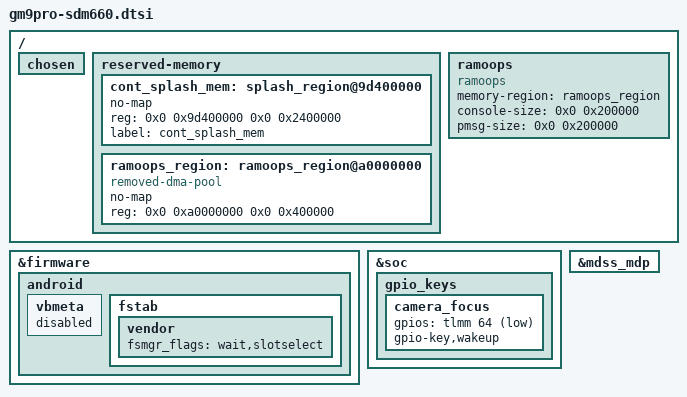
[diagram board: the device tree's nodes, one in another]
#include "gm9pro-pm660.dtsi"
#include "gm9pro-sdm660-audio.dtsi"
#include "gm9pro-sdm660-mdss.dtsi"
#include "gm9pro-sdm660-regulator.dtsi"
#include "gm9pro-sdm660-pinctrl.dtsi"

&firmware {
	android {
		vbmeta {
			status = "disabled";
		};

		fstab {
			vendor {
				fsmgr_flags = "wait,slotselect";
			};
		};
        };
};

&soc {
	gpio_keys {
		camera_focus {
			gpios = <&tlmm 64 1>;
			gpio-key,wakeup;
		};

		/delete-node/ camera_snapshot;
	};
};

/ {
	chosen {
		#address-cells = <2>;
		#size-cells = <2>;
		ranges;


	};
	reserved-memory {
		cont_splash_mem: splash_region@9d400000 {
			no-map;
			reg = <0x0 0x9d400000 0x0 0x2400000>;
			label = "cont_splash_mem";
		};

		ramoops_region: ramoops_region@a0000000 {
			compatible = "removed-dma-pool";
			no-map;
			reg = <0x0 0xa0000000 0x0 0x400000>;
		};
	};

	ramoops {
		compatible = "ramoops";
		memory-region = <&ramoops_region>;
		console-size = <0x0 0x200000>;
		pmsg-size = <0x0 0x200000>;
	};
};

&mdss_mdp { status = "ok"; };
